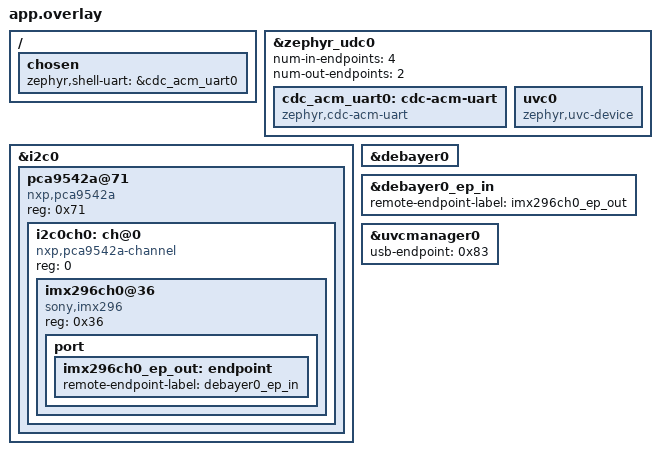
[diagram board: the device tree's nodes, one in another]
/*
 * Copyright (c) 2025 tinyVision.ai Inc.
 *
 * SPDX-License-Identifier: Apache-2.0
 */

/ {
	chosen {
		zephyr,shell-uart = &cdc_acm_uart0;
	};
};

/* USB interfaces */

&zephyr_udc0 {
	num-in-endpoints = <4>;
	num-out-endpoints = <2>;
	status = "okay";

	cdc_acm_uart0: cdc-acm-uart {
		compatible = "zephyr,cdc-acm-uart";
	};

	uvc0: uvc0 {
		compatible = "zephyr,uvc-device";
	};
};

/* I2C multiplexer */

&i2c0 {
	status = "okay";

	pca9542a@71 {
		compatible = "nxp,pca9542a";
		reg = <0x71>;
		#address-cells = <1>;
		#size-cells = <0>;

		i2c0ch0: ch@0 {
			compatible = "nxp,pca9542a-channel";
			reg = <0>;
			#address-cells = <1>;
			#size-cells = <0>;
		};
	};
};

/* Stream 0 config */

&i2c0ch0 {
	imx296ch0@36 {
		compatible = "sony,imx296";
		reg = <0x36>;

		port {
			imx296ch0_ep_out: endpoint {
				remote-endpoint-label = "debayer0_ep_in";
			};
		};
	};
};

&debayer0 {
	status = "okay";
};

&debayer0_ep_in {
	remote-endpoint-label = "imx296ch0_ep_out";
};

&uvcmanager0 {
	/* From UVC's "bEndpointAddress" in "lsusb -v -d 1209:0001" output */
	usb-endpoint = <0x83>;
	status = "okay";
};
